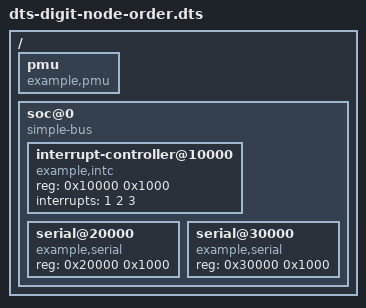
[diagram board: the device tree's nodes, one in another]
// SPDX-License-Identifier: GPL-2.0-only OR BSD-2-Clause
/ {
	#address-cells = <1>;
	#size-cells = <1>;

	/* TODO: uncomment when child-address-order is fixed for top-level */
	/*
	memory@a0000000 {
		device_type = "memory";
		reg = <0x0 0xa0000000 0x0 0x0>;
	};
	*/

	pmu {
		compatible = "example,pmu";
	};

	soc@0 {
		compatible = "simple-bus";
		ranges = <0 0 0 0xc0000000>;

		#address-cells = <1>;
		#size-cells = <1>;

		interrupt-controller@10000 {
			compatible = "example,intc";
			reg = <0x10000 0x1000>;
			interrupts = <1 2 3>;
		};

		serial@20000 {
			compatible = "example,serial";
			reg = <0x20000 0x1000>;
		};

		serial@30000 {
			compatible = "example,serial";
			reg = <0x30000 0x1000>;
		};
	};
};
